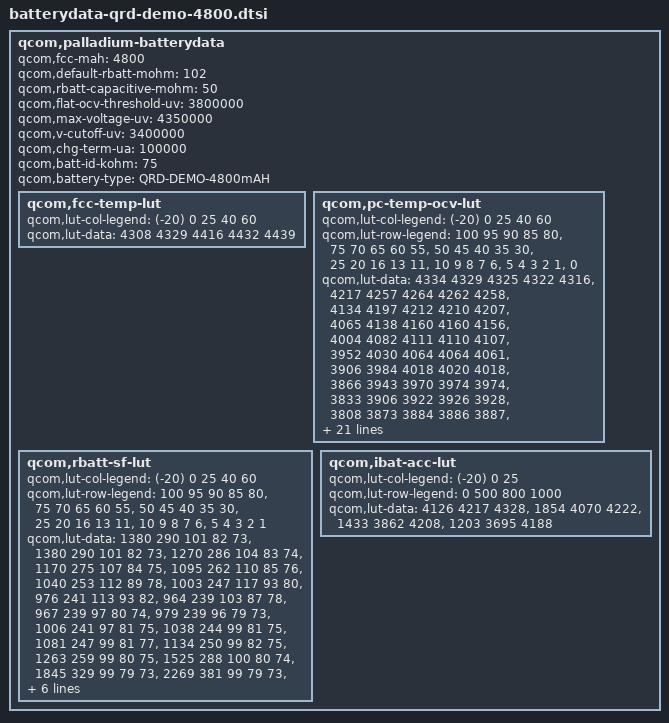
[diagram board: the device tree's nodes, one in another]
/* Copyright (c) 2013-2014, The Linux Foundation. All rights reserved.
 *
 * This program is free software; you can redistribute it and/or modify
 * it under the terms of the GNU General Public License version 2 and
 * only version 2 as published by the Free Software Foundation.
 *
 * This program is distributed in the hope that it will be useful,
 * but WITHOUT ANY WARRANTY; without even the implied warranty of
 * MERCHANTABILITY or FITNESS FOR A PARTICULAR PURPOSE.  See the
 * GNU General Public License for more details.
 */

qcom,palladium-batterydata {
	qcom,fcc-mah = <4800>;
	qcom,default-rbatt-mohm = <102>;
	qcom,rbatt-capacitive-mohm = <50>;
	qcom,flat-ocv-threshold-uv = <3800000>;
	qcom,max-voltage-uv = <4350000>;
	qcom,v-cutoff-uv = <3400000>;
	qcom,chg-term-ua = <100000>;
	qcom,batt-id-kohm = <75>;
	qcom,battery-type = "QRD-DEMO-4800mAH";

	qcom,fcc-temp-lut {
		qcom,lut-col-legend = <(-20) 0 25 40 60>;
		qcom,lut-data = <4308 4329 4416 4432 4439>;
	};

	qcom,pc-temp-ocv-lut {
		qcom,lut-col-legend = <(-20) 0 25 40 60>;
		qcom,lut-row-legend = <100 95 90 85 80>,
					<75 70 65 60 55>,
					<50 45 40 35 30>,
					<25 20 16 13 11>,
					<10 9 8 7 6>,
					<5 4 3 2 1>,
					<0>;
		qcom,lut-data = <4334 4329 4325 4322 4316>,
				<4217 4257 4264 4262 4258>,
				<4134 4197 4212 4210 4207>,
				<4065 4138 4160 4160 4156>,
				<4004 4082 4111 4110 4107>,
				<3952 4030 4064 4064 4061>,
				<3906 3984 4018 4020 4018>,
				<3866 3943 3970 3974 3974>,
				<3833 3906 3922 3926 3928>,
				<3808 3873 3884 3886 3887>,
				<3786 3843 3856 3857 3858>,
				<3766 3816 3831 3832 3832>,
				<3746 3790 3809 3810 3810>,
				<3726 3766 3788 3789 3788>,
				<3702 3743 3769 3768 3762>,
				<3675 3724 3748 3747 3737>,
				<3642 3708 3722 3719 3708>,
				<3610 3694 3700 3695 3684>,
				<3576 3677 3684 3678 3668>,
				<3554 3664 3680 3675 3665>,
				<3537 3648 3678 3673 3664>,
				<3518 3634 3674 3672 3660>,
				<3500 3618 3660 3654 3643>,
				<3482 3603 3638 3636 3626>,
				<3458 3569 3616 3618 3609>,
				<3426 3530 3582 3579 3570>,
				<3393 3492 3528 3532 3526>,
				<3360 3433 3471 3476 3474>,
				<3306 3354 3399 3406 3410>,
				<3252 3275 3312 3314 3322>,
				<3200 3200 3200 3200 3200>;
	};

	qcom,rbatt-sf-lut {
		qcom,lut-col-legend = <(-20) 0 25 40 60>;
		qcom,lut-row-legend = <100 95 90 85 80>,
					<75 70 65 60 55>,
					<50 45 40 35 30>,
					<25 20 16 13 11>,
					<10 9 8 7 6>,
					<5 4 3 2 1>;
		qcom,lut-data = <1380 290 101 82 73>,
				<1380 290 101 82 73>,
				<1270 286 104 83 74>,
				<1170 275 107 84 75>,
				<1095 262 110 85 76>,
				<1040 253 112 89 78>,
				<1003 247 117 93 80>,
				<976 241 113 93 82>,
				<964 239 103 87 78>,
				<967 239 97 80 74>,
				<979 239 96 79 73>,
				<1006 241 97 81 75>,
				<1038 244 99 81 75>,
				<1081 247 99 81 77>,
				<1134 250 99 82 75>,
				<1263 259 99 80 75>,
				<1525 288 100 80 74>,
				<1845 329 99 79 73>,
				<2269 381 99 79 73>,
				<2550 420 107 84 75>,
				<2823 449 111 86 77>,
				<3126 480 116 89 78>,
				<3431 509 120 91 79>,
				<3734 539 122 91 79>,
				<4216 597 124 94 80>,
				<5044 662 129 96 82>,
				<5875 726 137 98 84>,
				<6772 1052 153 108 91>,
				<9010 1667 198 131 100>,
				<11320 2756 396 246 127>;
	};

	qcom,ibat-acc-lut {
		qcom,lut-col-legend = <(-20) 0 25>;
		qcom,lut-row-legend = <0 500 800 1000>;
        qcom,lut-data = <4126 4217 4328>,
				<1854 4070 4222>,
				<1433 3862 4208>,
				<1203 3695 4188>;
	};
};
